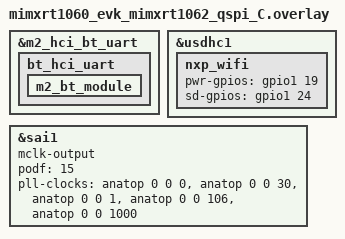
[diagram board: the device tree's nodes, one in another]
/*
 * Copyright 2026 NXP
 *
 * SPDX-License-Identifier: Apache-2.0
 */

&m2_hci_bt_uart {
	bt_hci_uart: bt_hci_uart {
	 m2_bt_module: m2_bt_module {
		/delete-property/ sdio-reset-gpios;
		/delete-property/ w-disable-gpios;
		};
	};
};

&usdhc1 {
	nxp_wifi {
		pwr-gpios = <&gpio1 19 GPIO_ACTIVE_HIGH>;
		sd-gpios = <&gpio1 24 GPIO_ACTIVE_HIGH>;
	};
};

&sai1 {
	mclk-output;
	podf = <15>;
	pll-clocks = <&anatop 0 0 0>,
		     <&anatop 0 0 30>,
		     <&anatop 0 0 1>,
		     <&anatop 0 0 106>,
		     <&anatop 0 0 1000>;
};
